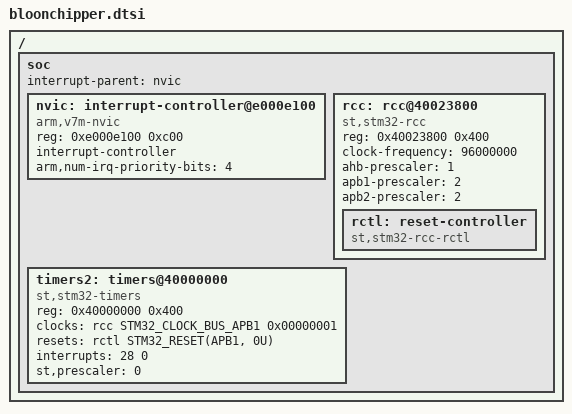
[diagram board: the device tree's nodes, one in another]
/* Copyright 2023 The ChromiumOS Authors
 * Use of this source code is governed by a BSD-style license that can be
 * found in the LICENSE file.
 */

#include <zephyr/dt-bindings/clock/stm32f4_clock.h>
#include <zephyr/dt-bindings/reset/stm32f2_4_7_reset.h>
#include "../native_posix.overlay"

/ {
	soc {
		#address-cells = <1>;
		#size-cells = <0>;
		interrupt-parent = <&nvic>;
		ranges;

		nvic: interrupt-controller@e000e100  {
			#address-cells = <1>;
			compatible = "arm,v7m-nvic";
			reg = <0xe000e100 0xc00>;
			interrupt-controller;
			#interrupt-cells = <2>;
			arm,num-irq-priority-bits = <4>;
		};

		rcc: rcc@40023800 {
			compatible = "st,stm32-rcc";

			#clock-cells = <2>;

			reg = <0x40023800 0x400>;
			clock-frequency = <96000000>;
			ahb-prescaler = <1>;
			apb1-prescaler = <2>;
			apb2-prescaler = <2>;

			rctl: reset-controller {
				compatible = "st,stm32-rcc-rctl";
				#reset-cells = <1>;
			};
		};

		timers2: timers@40000000 {
			compatible = "st,stm32-timers";
			reg = <0x40000000 0x400>;
			clocks = <&rcc STM32_CLOCK_BUS_APB1 0x00000001>;
			resets = <&rctl STM32_RESET(APB1, 0U)>;
			interrupts = <28 0>;
			interrupt-names = "global";
			st,prescaler = <0>;
		};
	};
};
